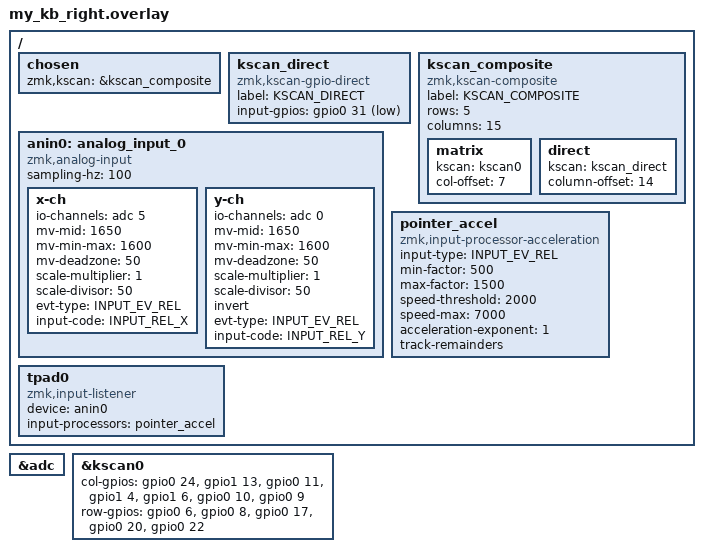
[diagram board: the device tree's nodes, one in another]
#include "my_kb.dtsi"
#include <input/processors.dtsi>
#include <behaviors/input_gestures_accel.dtsi>


/ {
    chosen {
        zmk,kscan = &kscan_composite;
    };
    //アナログパッドのボタン
    kscan_direct: kscan_direct {
        compatible = "zmk,kscan-gpio-direct";
        // 任意のラベル（ログ確認用など）
        label = "KSCAN_DIRECT";
        input-gpios
            = <&gpio0 31 (GPIO_ACTIVE_LOW | GPIO_PULL_UP)> 
            ;
    };
    kscan_composite: kscan_composite {
        compatible = "zmk,kscan-composite";
        label = "KSCAN_COMPOSITE";
        rows = <5>; 
        columns = <15>;

        // 既存の行列マトリックスを composite に割り当て (row_offset = 0)
        matrix {
            kscan = <&kscan0>;
            col-offset = <7>;
        };

        direct {
            kscan = <&kscan_direct>;
            column-offset = <14>;
        };
    };
    //アナログパッドの設定
    anin0: analog_input_0 {
        compatible = "zmk,analog-input";
        sampling-hz = <100>;
        x-ch {
            io-channels = <&adc 5>;
            mv-mid = <1650>;
            mv-min-max = <1600>;
            mv-deadzone = <50>;
            scale-multiplier = <1>;
            scale-divisor = <50>;
            evt-type = <INPUT_EV_REL>;
            input-code = <INPUT_REL_X>;
        };
        y-ch {
            io-channels = <&adc 0>;
            mv-mid = <1650>;
            mv-min-max = <1600>;
            mv-deadzone = <50>;
            scale-multiplier = <1>;
            scale-divisor = <50>;
            invert;
            evt-type = <INPUT_EV_REL>;
            input-code = <INPUT_REL_Y>;
        };
    };
    // マウスポインタのアナログパッド
    pointer_accel: pointer_accel {
        compatible = "zmk,input-processor-acceleration";
        #input-processor-cells = <0>;
        input-type = <INPUT_EV_REL>; 
        min-factor = <500>;
        max-factor = <1500>;
        speed-threshold = <2000>;
        speed-max = <7000>;
        acceleration-exponent = <1>;
        track-remainders;
    };

    tpad0: tpad0 {
        compatible = "zmk,input-listener";
        status = "okay";
        device = <&anin0>;
        input-processors = <&pointer_accel>;
    };
};

&adc {
    status = "okay";
};

&kscan0 {
    col-gpios
        = <&gpio0 24 GPIO_ACTIVE_HIGH>
        , <&gpio1 13 GPIO_ACTIVE_HIGH>
        , <&gpio0 11 GPIO_ACTIVE_HIGH>
        , <&gpio1  4 GPIO_ACTIVE_HIGH>
        , <&gpio1  6 GPIO_ACTIVE_HIGH>
        , <&gpio0 10 GPIO_ACTIVE_HIGH>
        , <&gpio0  9 GPIO_ACTIVE_HIGH>
        ;

    row-gpios
        = <&gpio0  6 (GPIO_ACTIVE_HIGH | GPIO_PULL_DOWN)>
        , <&gpio0  8 (GPIO_ACTIVE_HIGH | GPIO_PULL_DOWN)>
        , <&gpio0 17 (GPIO_ACTIVE_HIGH | GPIO_PULL_DOWN)>
        , <&gpio0 20 (GPIO_ACTIVE_HIGH | GPIO_PULL_DOWN)>
        , <&gpio0 22 (GPIO_ACTIVE_HIGH | GPIO_PULL_DOWN)>
        ;    
};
